# S6E1C3xD register map
Vendor: Cypress; File version: 2.1
CPU: CM0PLUS r0p1, little endian, no MPU, no FPU, 2 interrupt priority bits
Registers are 32-bit, read-write, reset 0x0 unless marked. A register's access mark holds for its fields unless they carry their own. Offsets are from the block's base; [hi:lo] are bit positions.

## USBCLK — USB/Ethernet Clock
Base 0x40036000
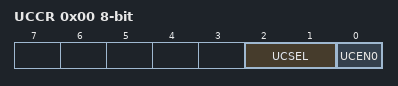
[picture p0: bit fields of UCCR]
0x00 UCCR 8-bit — USB Clock Control Register [BHW]
  [2:1] UCSEL — USB clock selection bits
  [0] UCEN0 — USB0 clock output enable bit
0x28 UPCR6 8-bit reset 0x2 — USB Frequency Divider Register [BHW]
  [3:0] UBSR — Frequency division ratio setting bits of the PLLOUT clock
0x30 USBEN0 8-bit reset 0x4 — USB0 Enable Register [BHW]
  [0] USBEN0 — USB0 enable bit

## I2CSLAVE — I2C Slave Wakeup
Base 0x40037980
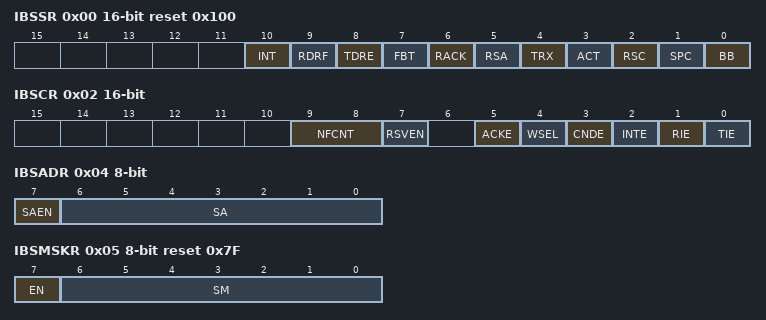
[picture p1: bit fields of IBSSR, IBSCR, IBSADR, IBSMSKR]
0x00 IBSSR 16-bit ro reset 0x100 — I2C Bus Slave Status Register [BHW]
  [10] INT — Status Interrupt Request flag
  [9] RDRF — Reception Interrupt Request flag
  [8] TDRE — Transmission Data Empty flag
  [7] FBT — First Byte flag
  [6] RACK — Acknowledge flag
  [5] RSA — Reserved Address Detection flag
  [4] TRX — Data Direction flag
  [3] ACT — Active flag
  [2] RSC — Re-Start Condition Detection flag
  [1] SPC — Stop Condition Detection flag
  [0] BB — Bus Busy flag
0x02 IBSCR 16-bit — I2C Bus Slave Control Register [BHW]
  [9:8] NFCNT — Noise Filter Control bits
  [7] RSVEN — Reserved Address Enable bit
  [5] ACKE — Acknowledge Enable bit
  [4] WSEL — Wait Select bit
  [3] CNDE — Condition Detection Interrupt Request Enable bit
  [2] INTE — Status Interrupt Request Enable bit
  [1] RIE — Reception Interrupt Request Enable bit
  [0] TIE — Transmission Interrupt Request Enable bit
0x04 IBSADR 8-bit — I2C Bus 7-bit Slave Address Register [BHW]
  [7] SAEN — Slave Address Enable bit
  [6:0] SA — Slave Address Value bit
0x05 IBSMSKR 8-bit reset 0x7F — I2C Bus 7-bit Slave Address Mask Register [BHW]
  [7] EN — Operating Enable bit
  [6:0] SM — Slave Address Mask bit
0x06 IBSDSTUPR 8-bit reset 0xFF — I2C Bus Slave Data Setup Register [BHW]
  [7:0] SETUP — Setup bits
0x08 IBSTDR 8-bit reset 0xFF — I2C Bus Slave Transmission Data Register [BHW]
  [7:0] TDR — Transmission Data bits
0x0C IBSRDR 8-bit ro reset 0xFF — I2C Bus Slave Reception Data Register [BHW]
  [7:0] RDR — Reception Data bis
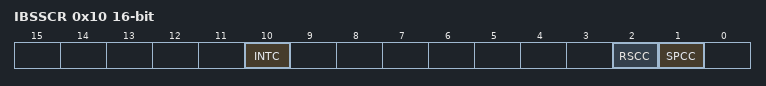
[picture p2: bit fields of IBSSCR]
0x10 IBSSCR 16-bit wo — I2C Bus Slave Status Clear Register [BHW]
  [10] INTC — Status Interrupt Request Flag Clear bit
  [2] RSCC — Re-Start Condition Detection Flag Clear bit
  [1] SPCC — Stop Condition Detection Flag Clear bit
0x14 IBSSSR 16-bit wo — I2C Bus Slave Status Set Register [BHW]
  [8] TDRES — Transmission Data Empty Flag Set bit

## CRC — CRC Registers
Base 0x40039000
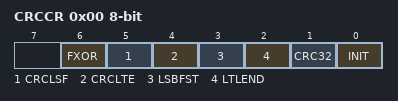
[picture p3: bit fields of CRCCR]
0x00 CRCCR 8-bit — CRC Control Register [BHW]
  [6] FXOR — Final XOR control bit
  [5] CRCLSF — CRC result bit-order setting bit
  [4] CRCLTE — CRC result byte-order setting bit
  [3] LSBFST — Bit-order setting bit
  [2] LTLEND — Byte-order setting bit
  [1] CRC32 — CRC mode selection bit
  [0] INIT — Initialization bit
0x04 CRCINIT reset 0xFFFFFFFF — Initial Value Register [BHW]
  [31:0] D — Initial value bits
0x08 CRCIN — Input Data Register [BHW]
  [31:0] D — Input data bits
0x0C CRCR ro reset 0xFFFFFFFF — CRC Register [BHW]
  [31:0] D — CRC bits

## WC — Watch Counter
Base 0x4003A000
0x00 WCRD 8-bit ro — Watch Counter Read Register [BHW]
  [5:0] CTR — Counter read bits
0x01 WCRL 8-bit — Watch Counter Reload Register [BHW]
  [5:0] RLC — Counter reload value setting bits
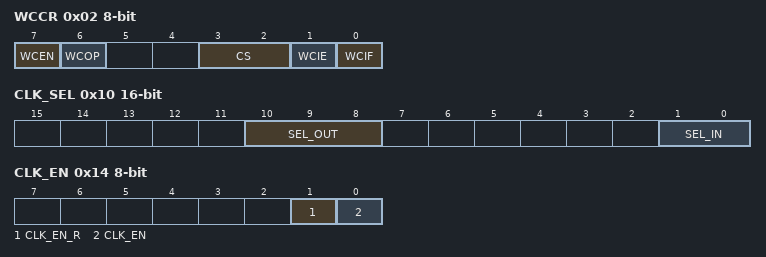
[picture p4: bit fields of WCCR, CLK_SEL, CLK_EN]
0x02 WCCR 8-bit — Watch Counter Control Register [BHW]
  [7] WCEN — Watch counter operation enable bit
  [6] WCOP ro — Watch counter operating state flag
  [3:2] CS — Count clock select bits
  [1] WCIE — Interrupt request enable bit
  [0] WCIF — Interrupt request flag bit
0x10 CLK_SEL 16-bit — Clock Selection Register [BHW]
  [10:8] SEL_OUT — Output clock selection bit
  [1:0] SEL_IN — Input clock selection bit
0x14 CLK_EN 8-bit — Division Clock Enable Register [BHW]
  [1] CLK_EN_R — Division clock enable read bit
  [0] CLK_EN — Division clock enable bit

## Notices in the file
Copyright (C) 2013-2016, Cypress Semiconductor Corporation or a
subsidiary of Cypress Semiconductor Corporation.  All rights reserved.
This software, including source code, documentation and related
materials ("Software"), is owned by Cypress Semiconductor Corporation or
one of its subsidiaries ("Cypress") and is protected by and subject to
worldwide patent protection (United States and foreign), United States
copyright laws and international treaty provisions. Therefore, you may use
this Software only as provided in the license agreement accompanying the
software package from which you obtained this Software ("EULA").
If no EULA applies, Cypress hereby grants you a personal, non-exclusive,
non-transferable license to copy, modify, and compile the
Software source code solely for use in connection with Cypress's
integrated circuit products.  Any reproduction, modification, translation,
compilation, or representation of this Software except as specified
above is prohibited without the express written permission of Cypress.
Disclaimer: THIS SOFTWARE IS PROVIDED AS-IS, WITH NO
WARRANTY OF ANY KIND, EXPRESS OR IMPLIED, INCLUDING,
BUT NOT LIMITED TO, NONINFRINGEMENT, IMPLIED
WARRANTIES OF MERCHANTABILITY AND FITNESS FOR A
PARTICULAR PURPOSE. Cypress reserves the right to make
changes to the Software without notice. Cypress does not assume any
liability arising out of the application or use of the Software or any
product or circuit described in the Software. Cypress does not
authorize its products for use in any products where a malfunction or
failure of the Cypress product may reasonably be expected to result in
significant property damage, injury or death ("High Risk Product"). By
including Cypress's product in a High Risk Product, the manufacturer
of such system or application assumes all risk of such use and in doing
so agrees to indemnify Cypress against all liability.
